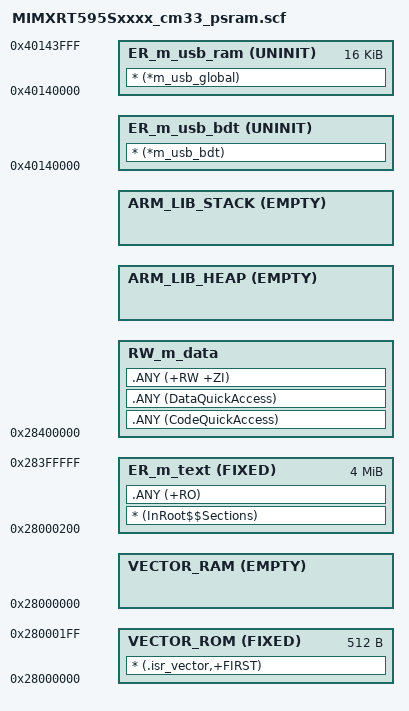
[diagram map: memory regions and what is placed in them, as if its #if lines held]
#!armclang --target=arm-arm-none-eabi -march=armv8-m.main -E -x c
/*
** ###################################################################
**     Processors:          MIMXRT595SFAWC_cm33
**                          MIMXRT595SFFOC_cm33
**     Compiler:            Keil ARM C/C++ Compiler
**     Reference manual:    RT500 Reference Manual. Rev.A, 3/2020
**     Version:             rev. 3.0, 2019-12-10
**     Build:               b200410
**
**     Abstract:
**         Linker file for the Keil ARM C/C++ Compiler
**
**     Copyright 2016 Freescale Semiconductor, Inc.
**     Copyright 2016-2020 NXP
**     All rights reserved.
**
**     SPDX-License-Identifier: BSD-3-Clause
**
**     http:                 www.nxp.com
**     mail:                 support@nxp.com
**
** ###################################################################
*/


/* USB BDT size */
#define usb_bdt_size                   0x0
/* Sizes */
#if (defined(__stack_size__))
  #define Stack_Size                   __stack_size__
#else
  #define Stack_Size                   0x0400
#endif

#if (defined(__heap_size__))
  #define Heap_Size                    __heap_size__
#else
  #define Heap_Size                    0x0400
#endif

/* The SRAM region [0x10000-0x1BFFF] is reserved for ROM code. */
/* The SRAM region [0x0-0xFFFF], [0x1C000-0x1FFFF] is reserved for app-specific use cases. */
/* The SRAM region [0x20000-0x7FFFF] is reserved for Non-cached shared memory between M33 and DSP. */


#define  m_interrupts_start            0x28000000
#define  m_interrupts_size             0x00000200

#define  m_text_start                  0x28000200
#define  m_text_size                   0x003FFE00

#define  m_data_start                  0x28400000
#define  m_data_size                   0x00400000

#define  m_usb_sram_start              0x40140000
#define  m_usb_sram_size               0x00004000

LR_m_interrupts m_interrupts_start m_interrupts_size+m_text_size {
  VECTOR_ROM m_interrupts_start FIXED m_interrupts_size { ; load address = execution address
    * (.isr_vector,+FIRST)
  }

  ER_m_text m_text_start FIXED m_text_size { ; load address = execution address
    * (InRoot$$Sections)
    .ANY (+RO)
  }
  VECTOR_RAM m_interrupts_start EMPTY 0 {
  }
  RW_m_data m_data_start ALIGN 4 m_data_size-Stack_Size-Heap_Size { ; RW data
    .ANY (CodeQuickAccess)
    .ANY (DataQuickAccess)
    .ANY (+RW +ZI)
  }

  ARM_LIB_HEAP +0 EMPTY Heap_Size {    ; Heap region growing up
  }
  ARM_LIB_STACK m_data_start+m_data_size EMPTY -Stack_Size { ; Stack region growing down
  }

  ER_m_usb_bdt m_usb_sram_start UNINIT usb_bdt_size {
    * (*m_usb_bdt)
  }

  ER_m_usb_ram (m_usb_sram_start + usb_bdt_size) UNINIT (m_usb_sram_size - usb_bdt_size) {
    * (*m_usb_global)
  }
}
